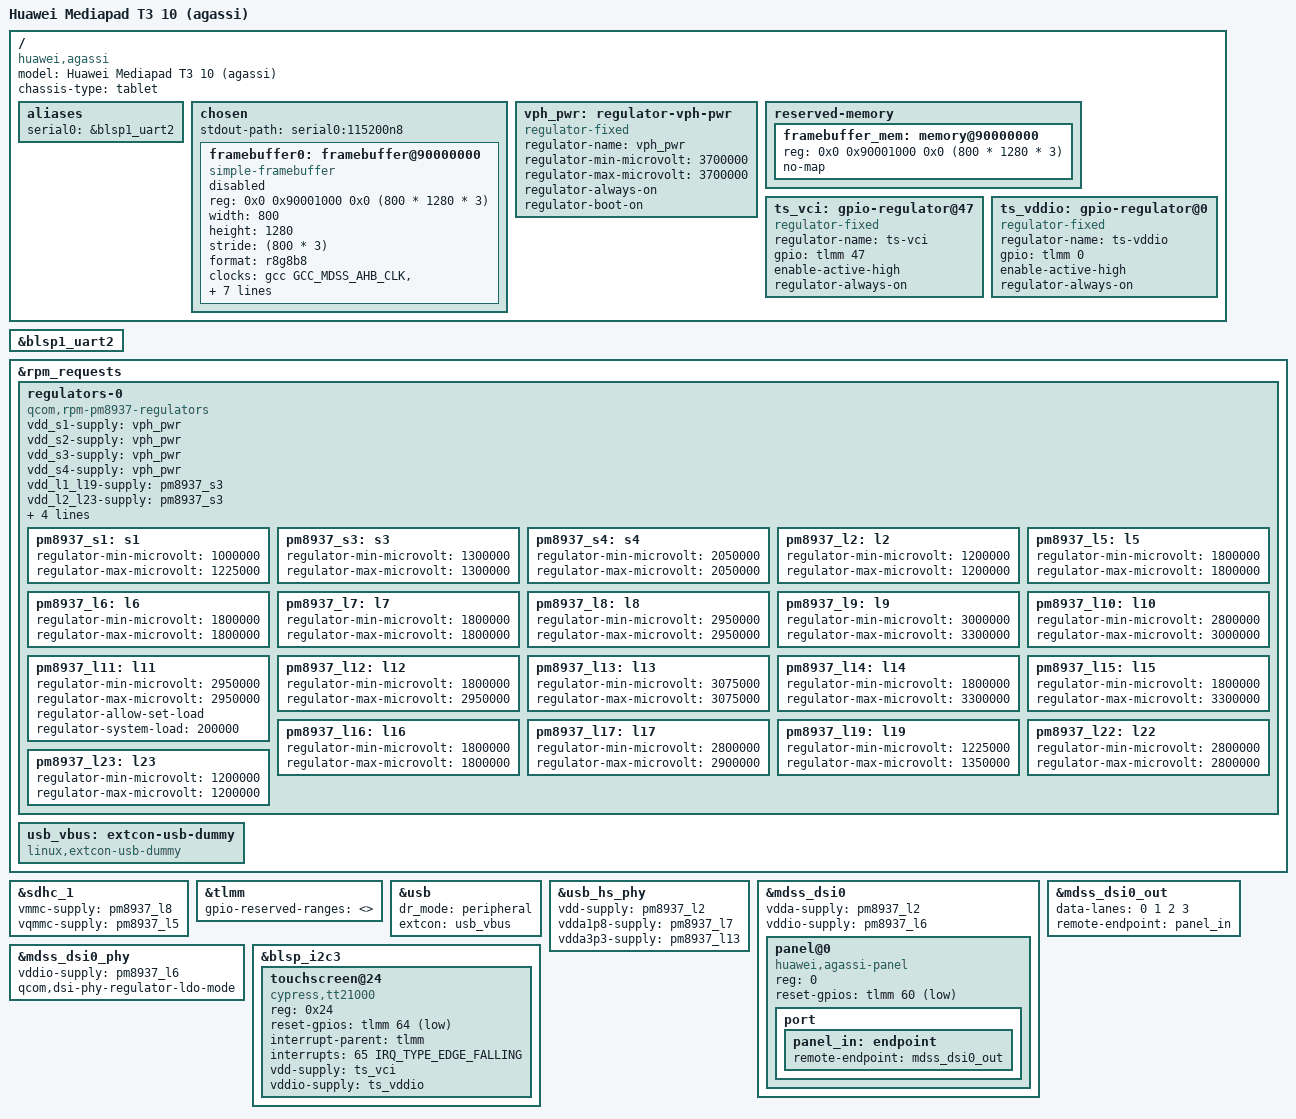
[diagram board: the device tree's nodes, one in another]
// SPDX-License-Identifier: GPL-2.0-only
/*
 * Copyright (c) 2023, Barnabas Czeman
 */

/dts-v1/;

#include <dt-bindings/arm/qcom,ids.h>
#include <dt-bindings/gpio/gpio.h>
#include <dt-bindings/input/linux-event-codes.h>
#include <dt-bindings/leds/common.h>
#include "msm8917.dtsi"
#include "pm8937.dtsi"

/delete-node/ &thermal_zones;

/ {
	model = "Huawei Mediapad T3 10 (agassi)";
	compatible = "huawei,agassi", "qcom,msm8917";
	chassis-type = "tablet";
	
	aliases {
		serial0 = &blsp1_uart2;
	};

	chosen {
		stdout-path = "serial0:115200n8";
		#address-cells = <2>;
		#size-cells = <2>;
		ranges;

		framebuffer0: framebuffer@90000000 {
			status = "disabled";
			compatible = "simple-framebuffer";
			reg = <0x0 0x90001000 0x0 (800 * 1280 * 3)>;
			width = <800>;
			height = <1280>;
			stride = <(800 * 3)>;
			format = "r8g8b8";

			clocks = <&gcc GCC_MDSS_AHB_CLK>,
				 <&gcc GCC_MDSS_AXI_CLK>,
				 <&gcc GCC_MDSS_VSYNC_CLK>,
				 <&gcc GCC_MDSS_MDP_CLK>,
				 <&gcc GCC_MDSS_BYTE0_CLK>,
				 <&gcc GCC_MDSS_PCLK0_CLK>,
				 <&gcc GCC_MDSS_ESC0_CLK>;
			power-domains = <&gcc MDSS_GDSC>;
		};
	};

	vph_pwr: regulator-vph-pwr {
		compatible = "regulator-fixed";
		regulator-name = "vph_pwr";
		regulator-min-microvolt = <3700000>;
		regulator-max-microvolt = <3700000>;
		regulator-always-on;
		regulator-boot-on;
	};

	reserved-memory {
		framebuffer_mem: memory@90000000 {
			reg = <0x0 0x90001000 0x0 (800 * 1280 * 3)>;
			no-map;
		};
	};

	ts_vci: gpio-regulator@47 {
		compatible = "regulator-fixed";
		regulator-name = "ts-vci";
		gpio = <&tlmm 47 GPIO_ACTIVE_HIGH>;
		enable-active-high;
		regulator-always-on;
	};

	ts_vddio: gpio-regulator@0 {
		compatible = "regulator-fixed";
		regulator-name = "ts-vddio";
		gpio = <&tlmm 0 GPIO_ACTIVE_HIGH>;
		enable-active-high;
		regulator-always-on;
	};
};

&blsp1_uart2 {
	status = "okay";
};

&rpm_requests {
	regulators-0 {
		// Regulators OK
		compatible = "qcom,rpm-pm8937-regulators";

		vdd_s1-supply = <&vph_pwr>;
		vdd_s2-supply = <&vph_pwr>;
		vdd_s3-supply = <&vph_pwr>;
		vdd_s4-supply = <&vph_pwr>;

		vdd_l1_l19-supply = <&pm8937_s3>;
		vdd_l2_l23-supply = <&pm8937_s3>;
		vdd_l3-supply = <&pm8937_s3>;
		vdd_l4_l5_l6_l7_l16-supply = <&pm8937_s4>;
		vdd_l8_l11_l12_l17_l22-supply = <&vph_pwr>;
		vdd_l9_l10_l13_l14_l15_l18-supply = <&vph_pwr>;

		pm8937_s1: s1 {
			regulator-min-microvolt = <1000000>;
			regulator-max-microvolt = <1225000>;
		};

		pm8937_s3: s3 {
			regulator-min-microvolt = <1300000>;
			regulator-max-microvolt = <1300000>;
		};

		pm8937_s4: s4 {
			regulator-min-microvolt = <2050000>;
			regulator-max-microvolt = <2050000>;
		};

		pm8937_l2: l2 {
			regulator-min-microvolt = <1200000>;
			regulator-max-microvolt = <1200000>;
		};

		pm8937_l5: l5 {
			regulator-min-microvolt = <1800000>;
			regulator-max-microvolt = <1800000>;
		};

		pm8937_l6: l6 {
			regulator-min-microvolt = <1800000>;
			regulator-max-microvolt = <1800000>;
		};

		pm8937_l7: l7 {
			regulator-min-microvolt = <1800000>;
			regulator-max-microvolt = <1800000>;
		};

		pm8937_l8: l8 {
			regulator-min-microvolt = <2950000>;
			regulator-max-microvolt = <2950000>;
		};

		pm8937_l9: l9 {
			regulator-min-microvolt = <3000000>;
			regulator-max-microvolt = <3300000>;
		};

		pm8937_l10: l10 {
			regulator-min-microvolt = <2800000>;
			regulator-max-microvolt = <3000000>;
		};

		pm8937_l11: l11 {
			regulator-min-microvolt = <2950000>;
			regulator-max-microvolt = <2950000>;
			regulator-allow-set-load;
			regulator-system-load = <200000>;
		};

		pm8937_l12: l12 {
			regulator-min-microvolt = <1800000>;
			regulator-max-microvolt = <2950000>;
		};

		pm8937_l13: l13 {
			regulator-min-microvolt = <3075000>;
			regulator-max-microvolt = <3075000>;
		};

		pm8937_l14: l14 {
			regulator-min-microvolt = <1800000>;
			regulator-max-microvolt = <3300000>;
		};

		pm8937_l15: l15 {
			regulator-min-microvolt = <1800000>;
			regulator-max-microvolt = <3300000>;
		};

		pm8937_l16: l16 {
			regulator-min-microvolt = <1800000>;
			regulator-max-microvolt = <1800000>;
		};

		pm8937_l17: l17 {
			regulator-min-microvolt = <2800000>;
			regulator-max-microvolt = <2900000>;
		};

		pm8937_l19: l19 {
			regulator-min-microvolt = <1225000>;
			regulator-max-microvolt = <1350000>;
		};

		pm8937_l22: l22 {
			regulator-min-microvolt = <2800000>;
			regulator-max-microvolt = <2800000>;
		};

		pm8937_l23: l23 {
			regulator-min-microvolt = <1200000>;
			regulator-max-microvolt = <1200000>;
		};
	};

	usb_vbus: extcon-usb-dummy {
		compatible = "linux,extcon-usb-dummy";
	};

};

&sdhc_1 {
	vmmc-supply = <&pm8937_l8>;
	vqmmc-supply = <&pm8937_l5>;

	status = "okay";
};

&tlmm {
	gpio-reserved-ranges =  <>; // Do not reserve gpio 0;
};

&usb {
	dr_mode = "peripheral";
	extcon = <&usb_vbus>;
	status = "okay";
};

&usb_hs_phy {
	vdd-supply = <&pm8937_l2>;
	vdda1p8-supply = <&pm8937_l7>;
	vdda3p3-supply = <&pm8937_l13>;
	status = "okay";
};

&mdss_dsi0 {
	vdda-supply = <&pm8937_l2>;
	vddio-supply = <&pm8937_l6>;
	panel@0 {
		compatible = "huawei,agassi-panel";
		reg = <0>;

		reset-gpios = <&tlmm 60 GPIO_ACTIVE_LOW>;
		// TODO: regulators and backlight controll

		port {
			panel_in: endpoint {
				remote-endpoint = <&mdss_dsi0_out>;
			};
		};
	};
};

&mdss_dsi0_out {
	data-lanes = <0 1 2 3>;
	remote-endpoint = <&panel_in>;
};

&mdss_dsi0_phy {
	vddio-supply = <&pm8937_l6>;
	qcom,dsi-phy-regulator-ldo-mode;
};

&blsp_i2c3 {
	status = "okay";

	touchscreen@24 {
		compatible = "cypress,tt21000";

		reg = <0x24>;
		reset-gpios = <&tlmm 64 GPIO_ACTIVE_LOW>;
		interrupt-parent = <&tlmm>;
		interrupts = <65 IRQ_TYPE_EDGE_FALLING>;

		vdd-supply = <&ts_vci>;
		vddio-supply = <&ts_vddio>;
	};
};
